# MPS3_SSE_200 register map
Vendor: ARM Ltd.; Series: ARMv8-M Mainline; File version: 1.0
CPU: CM33 r0p2, little endian, MPU, no FPU, 4 interrupt priority bits, 8 SAU regions
Registers are 32-bit, read-write, reset 0x0 unless marked. A register's access mark holds for its fields unless they carry their own. Offsets are from the block's base; [hi:lo] are bit positions.

## UART0
Base 0x41303000
Same registers: UART1 0x41304000, UART2 0x41305000, UART3 0x41306000, UART4 0x41307000, UART5 0x41308000, UART0_Secure 0x51303000, UART1_Secure 0x51304000, UART2_Secure 0x51305000, UART3_Secure 0x51306000, UART4_Secure 0x51307000, UART5_Secure 0x51308000
0x00 DATA 8-bit — Receive and Transmit Data Value
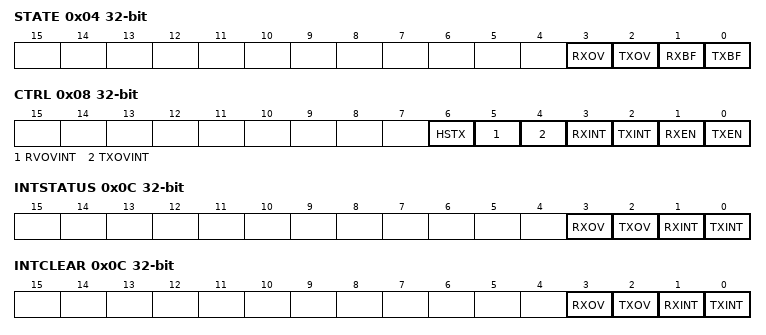
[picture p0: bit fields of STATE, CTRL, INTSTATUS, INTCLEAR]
0x04 STATE — UART Status Register
  [3] RXOV write-1-clears — RX Buffer Overun (write 1 to clear)
  [2] TXOV write-1-clears — TX Buffer Overun (write 1 to clear)
  [1] RXBF ro — RX Buffer Full
  [0] TXBF ro — TX Buffer Full
0x08 CTRL — UART Control Register
  [all] fields
    0=Disabled; 1=Enabled
  [6] HSTX — High Speed Test Mode for TX only
  [5] RVOVINT — RX Overrun Interrupt Enable
  [4] TXOVINT — TX Overrun Interrupt Enable
  [3] RXINT — RX Interrupt Enable
  [2] TXINT — TX Interrupt Enable
  [1] RXEN — RX Enable
  [0] TXEN — TX Enable
0x0C INTSTATUS ro — UART Interrupt Status Register
  [3] RXOV — RX Overrun Interrupt
  [2] TXOV — TX Overrun Interrupt
  [1] RXINT — RX Interrupt
  [0] TXINT — TX Interrupt
0x0C INTCLEAR wo (alternate view of INTSTATUS) — UART Interrupt CLEAR Register
  [3] RXOV write-1-clears — RX Overrun Interrupt
  [2] TXOV write-1-clears — TX Overrun Interrupt
  [1] RXINT write-1-clears — RX Interrupt
  [0] TXINT write-1-clears — TX Interrupt
0x10 BAUDDIV — Baudrate Divider

## GPIO0 — General-purpose I/O 0
Base 0x41100000
Same registers: GPIO1 0x41101000, GPIO2 0x41102000, GPIO3 0x41103000, GPIO0_Secure 0x51100000, GPIO1_Secure 0x51101000, GPIO2_Secure 0x51102000, GPIO3_Secure 0x51103000
0x00 DATA
0x04 DATAOUT — Data Output Register
0x10 OUTENSET — Ouptut enable set Register
0x14 OUTENCLR — Ouptut enable clear Register
0x18 ALTFUNCSET — Alternate function set Register
0x1C ALTFUNCCLR — Alternate function clear Register
0x20 INTENSET — Interrupt enable set Register
0x24 INTENCLR — Interrupt enable clear Register
0x28 INTTYPESET — Interrupt type set Register
0x2C INTTYPECLR — Interrupt type clear Register
0x30 INTPOLSET — Polarity-level, edge interrupt configuration set Register
0x34 INTPOLCLR — Polarity-level, edge interrupt configuration clear Register
0x38 INTSTATUS ro — Interrupt Status Register
0x38 INTCLEAR wo write-1-clears (alternate view of INTSTATUS) — Interrupt CLEAR Register

## I2C0
Base 0x41200000
Same registers: I2C1 0x41201000, I2C2 0x41205000, I2C3 0x41206000, I2C4 0x41208000, I2C0_Secure 0x51200000, I2C1_Secure 0x51201000, I2C2_Secure 0x51205000, I2C3_Secure 0x51206000, I2C4_Secure 0x51208000
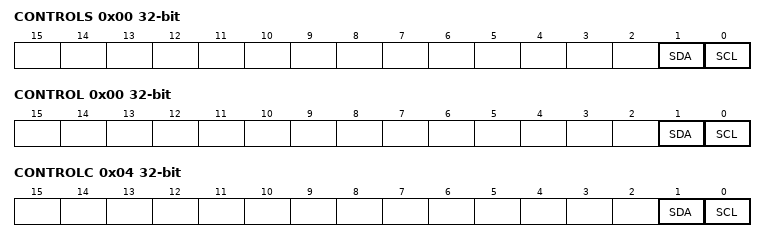
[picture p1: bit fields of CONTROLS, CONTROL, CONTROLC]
0x00 CONTROLS wo — Control Set
  [1] SDA — Serial data line
  [0] SCL — Serial clock line
0x00 CONTROL ro (alternate view of CONTROLS) — Control Status
  [1] SDA — Serial data line
  [0] SCL — Serial clock line
0x04 CONTROLC — Control Clear
  [1] SDA — Serial data line
  [0] SCL — Serial clock line

## WATCHDOG — Non-secure Watchdog Timer
Base 0x40081000
Same registers: S32KWATCHDOG_Secure 0x5002E000, WATCHDOG_Secure 0x50081000
0x00 WDOGLOAD reset 0xFFFFFFFF — Watchdog Load Register
0x04 WDOGVALUE ro reset 0xFFFFFFFF — Watchdog Value Register
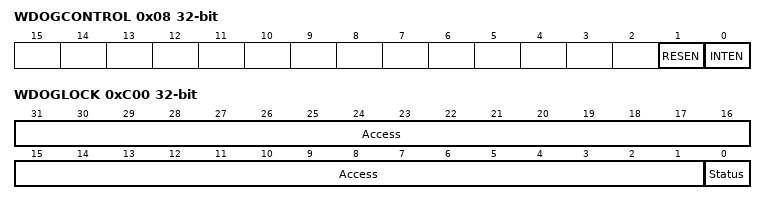
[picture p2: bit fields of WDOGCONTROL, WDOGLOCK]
0x08 WDOGCONTROL — Watchdog Control Register
  [1] RESEN — Enable watchdog reset output
    0=Disable Watchdog reset; 1=Enable Watchdog reset
  [0] INTEN — Enable the interrupt event
    0=Disable Watchdog interrupt; 1=Enable Watchdog interrupt
0x0C WDOGINTCLR wo — Watchdog Interrupt Clear Register
  [0] INT write-1-clears — Interrupt
0x10 WDOGRIS ro — Watchdog Raw Interrupt Status Register
  [0] RIS — Raw watchdog Interrupt
0x14 WDOGMIS ro — Watchdog Mask Interrupt Status Register
  [0] MIS — Masked Watchdog Interrupt
0xC00 WDOGLOCK — Watchdog Lock Register
  [31:1] Access — Enable register writes
  [0] Status — Register write enable status
    0=Enabled (Write access to all other registers is enabled. This is the default.); 1=Disabled (Write access to all other registers is disabled.)
